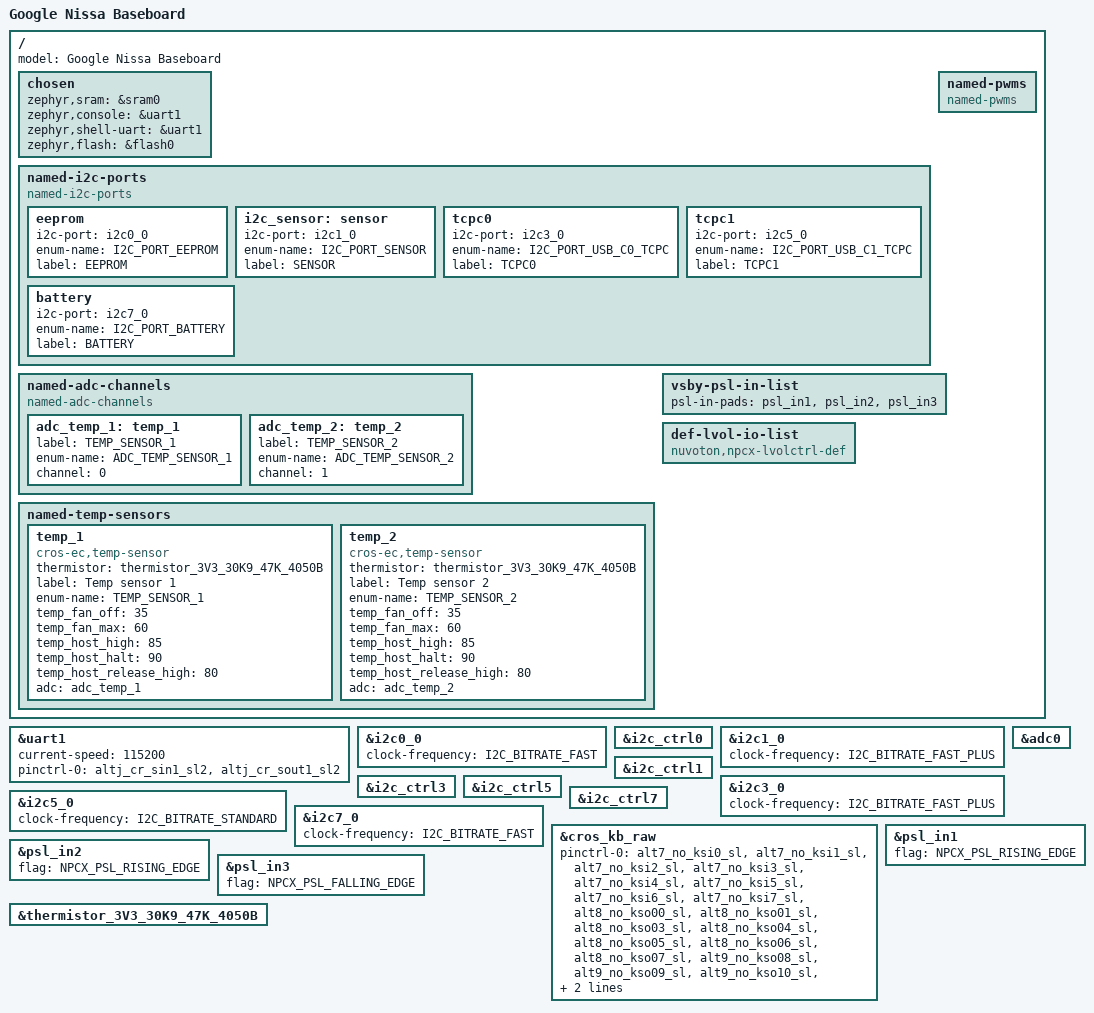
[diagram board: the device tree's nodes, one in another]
/* Copyright 2021 The Chromium OS Authors. All rights reserved.
 * Use of this source code is governed by a BSD-style license that can be
 * found in the LICENSE file.
 */

/dts-v1/;

#include <cros/nuvoton/npcx9.dtsi>
#include <cros/thermistor/thermistor.dtsi>
#include <dt-bindings/gpio_defines.h>
#include <nuvoton/npcx9m3f.dtsi>

/ {
	model = "Google Nissa Baseboard";

	chosen {
		zephyr,sram = &sram0;
		zephyr,console = &uart1;
		zephyr,shell-uart = &uart1;
		zephyr,flash = &flash0;
	};

	named-i2c-ports {
		compatible = "named-i2c-ports";
		eeprom {
			i2c-port = <&i2c0_0>;
			enum-name = "I2C_PORT_EEPROM";
			label = "EEPROM";
		};
		i2c_sensor: sensor {
			i2c-port = <&i2c1_0>;
			enum-name = "I2C_PORT_SENSOR";
			label = "SENSOR";
		};
		tcpc0 {
			i2c-port = <&i2c3_0>;
			enum-name = "I2C_PORT_USB_C0_TCPC";
			label = "TCPC0";
		};
		tcpc1 {
			i2c-port = <&i2c5_0>;
			enum-name = "I2C_PORT_USB_C1_TCPC";
			label = "TCPC1";
		};
		battery {
			i2c-port = <&i2c7_0>;
			enum-name = "I2C_PORT_BATTERY";
			label = "BATTERY";
		};
	};

	named-pwms {
		compatible = "named-pwms";
	};

	named-adc-channels {
		compatible = "named-adc-channels";

		adc_temp_1: temp_1 {
			label = "TEMP_SENSOR_1";
			enum-name = "ADC_TEMP_SENSOR_1";
			channel = <0>;
		};
		adc_temp_2: temp_2 {
			label = "TEMP_SENSOR_2";
			enum-name = "ADC_TEMP_SENSOR_2";
			channel = <1>;
		};
	};

	named-temp-sensors {
		temp_1 {
			compatible = "cros-ec,temp-sensor";
			thermistor = <&thermistor_3V3_30K9_47K_4050B>;
			label = "Temp sensor 1";
			enum-name = "TEMP_SENSOR_1";
			temp_fan_off = <35>;
			temp_fan_max = <60>;
			temp_host_high = <85>;
			temp_host_halt = <90>;
			temp_host_release_high = <80>;
			adc = <&adc_temp_1>;
		};
		temp_2 {
			compatible = "cros-ec,temp-sensor";
			thermistor = <&thermistor_3V3_30K9_47K_4050B>;
			label = "Temp sensor 2";
			enum-name = "TEMP_SENSOR_2";
			temp_fan_off = <35>;
			temp_fan_max = <60>;
			temp_host_high = <85>;
			temp_host_halt = <90>;
			temp_host_release_high = <80>;
			adc = <&adc_temp_2>;
		};
	};

	vsby-psl-in-list {
		/* Use PSL_IN1/2/3 as detection pins from hibernate mode */
		psl-in-pads = <&psl_in1 &psl_in2 &psl_in3>;
	};

	def-lvol-io-list {
		compatible = "nuvoton,npcx-lvolctrl-def";
	};
};

&uart1 {
	status = "okay";
	current-speed = <115200>;
	pinctrl-0 = <&altj_cr_sin1_sl2 &altj_cr_sout1_sl2>;
};

&i2c0_0 {
	status = "okay";
	clock-frequency = <I2C_BITRATE_FAST>;
};

&i2c_ctrl0 {
	status = "okay";
};

&i2c1_0 {
	status = "okay";
	clock-frequency = <I2C_BITRATE_FAST_PLUS>;
};

&i2c_ctrl1 {
	status = "okay";
};

&i2c3_0 {
	status = "okay";
	clock-frequency = <I2C_BITRATE_FAST_PLUS>;
};

&i2c_ctrl3 {
	status = "okay";
};

&i2c5_0 {
	status = "okay";
	clock-frequency = <I2C_BITRATE_STANDARD>;
};

&i2c_ctrl5 {
	status = "okay";
};

&i2c7_0 {
	status = "okay";
	clock-frequency = <I2C_BITRATE_FAST>;
};

&i2c_ctrl7 {
	status = "okay";
};

&cros_kb_raw {
	status = "okay";
	/* No KSO2 (it's inverted and implemented by GPIO) */
	pinctrl-0 = <&alt7_no_ksi0_sl
		     &alt7_no_ksi1_sl
		     &alt7_no_ksi2_sl
		     &alt7_no_ksi3_sl
		     &alt7_no_ksi4_sl
		     &alt7_no_ksi5_sl
		     &alt7_no_ksi6_sl
		     &alt7_no_ksi7_sl
		     &alt8_no_kso00_sl
		     &alt8_no_kso01_sl
		     &alt8_no_kso03_sl
		     &alt8_no_kso04_sl
		     &alt8_no_kso05_sl
		     &alt8_no_kso06_sl
		     &alt8_no_kso07_sl
		     &alt9_no_kso08_sl
		     &alt9_no_kso09_sl
		     &alt9_no_kso10_sl
		     &alt9_no_kso11_sl
		     &alt9_no_kso12_sl
		     &alt9_no_kso13_sl
		     &alt9_no_kso14_sl
		     >;
};

&adc0 {
	status = "okay";
};

/* Power switch logic input pads */
/* LID_OPEN_OD */
&psl_in1 {
	flag = <NPCX_PSL_RISING_EDGE>;
};

/* ACOK_EC_OD */
&psl_in2 {
	flag = <NPCX_PSL_RISING_EDGE>;
};

/* GSC_EC_PWR_BTN_ODL */
&psl_in3 {
	flag = <NPCX_PSL_FALLING_EDGE>;
};

&thermistor_3V3_30K9_47K_4050B {
	status = "okay";
};
